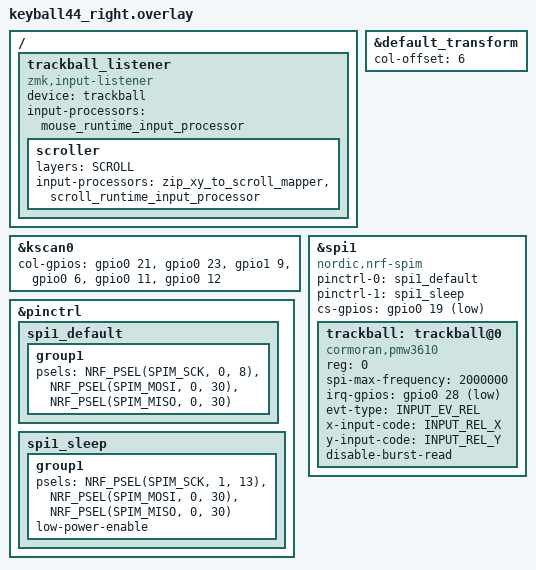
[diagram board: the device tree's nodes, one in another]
/*
 * Copyright (c) 2020 ZMK Contributors
 *
 * SPDX-License-Identifier: MIT
 */
#include "keyball44.dtsi"
#include <input/processors.dtsi>
#include <input/processors/runtime-input-processor.dtsi>
#include <behaviors/battery_history_request.dtsi>
#include <dt-bindings/zmk/input_transform.h>
#include <dt-bindings/zmk/keys.h>
#define QWERT  0
#define NAVI   1
#define SYMBOL    2
#define MODIFY 3
#define MOUSE  4
#define SCROLL 5
#define SNIPE  6
#define WIN    7
#define WINSYMBOL 9
#define WINMODIFY 10
#define WINSCROLL 11
#define WINSNIPE 12
#define WINMOUSE 14

&default_transform {
    col-offset = <6>;
};

&kscan0 {
	col-gpios
		= <&gpio0 21 GPIO_ACTIVE_HIGH>
		, <&gpio0 23 GPIO_ACTIVE_HIGH>
		, <&gpio1 9 GPIO_ACTIVE_HIGH>
		, <&gpio0 6 GPIO_ACTIVE_HIGH>
		, <&gpio0 11 GPIO_ACTIVE_HIGH>
		, <&gpio0 12 GPIO_ACTIVE_HIGH>
		;
};

&pinctrl {
    spi1_default: spi1_default {
        group1 {
            psels = <NRF_PSEL(SPIM_SCK, 0, 8)>,
                <NRF_PSEL(SPIM_MOSI, 0, 30)>,
                <NRF_PSEL(SPIM_MISO, 0, 30)>;
        };
    };

    spi1_sleep: spi1_sleep {
        group1 {
            psels = <NRF_PSEL(SPIM_SCK, 1, 13)>,
                <NRF_PSEL(SPIM_MOSI, 0, 30)>,
                <NRF_PSEL(SPIM_MISO, 0, 30)>;
            low-power-enable;
        };
    };
};

&spi1 {
    status = "okay";
    compatible = "nordic,nrf-spim";
    pinctrl-0 = <&spi1_default>;
    pinctrl-1 = <&spi1_sleep>;
    pinctrl-names = "default", "sleep";
    cs-gpios = <&gpio0 19 GPIO_ACTIVE_LOW>;

    trackball: trackball@0 {
        status = "okay";
        compatible = "cormoran,pmw3610";
        reg = <0>;
        spi-max-frequency = <2000000>;
        irq-gpios = <&gpio0 28 (GPIO_ACTIVE_LOW | GPIO_PULL_UP)>;
        evt-type = <INPUT_EV_REL>;
        x-input-code = <INPUT_REL_X>;
        y-input-code = <INPUT_REL_Y>;
        disable-burst-read;
    };
};

/ {
    trackball_listener {
        status = "okay";
        compatible = "zmk,input-listener";
        device = <&trackball>;
        input-processors = <&mouse_runtime_input_processor>;

        scroller {
            layers = <SCROLL>;
            input-processors = <&zip_xy_to_scroll_mapper &scroll_runtime_input_processor>;
        };
    };
};
